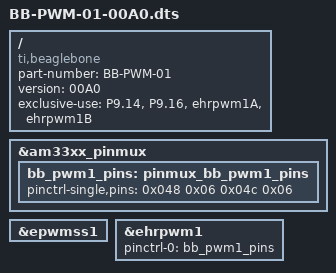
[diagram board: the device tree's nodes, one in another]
/dts-v1/;
/plugin/;

/*
 * BeagleBone Black PWM Overlay
 * Enables EHRPWM1A and EHRPWM1B on P9.14 and P9.16
 */

/ {
    compatible = "ti,beaglebone", "ti,beaglebone-black";
    
    /* identification */
    part-number = "BB-PWM-01";
    version = "00A0";
    
    /* state the resources this cape uses */
    exclusive-use =
        /* the pin header uses */
        "P9.14",    /* ehrpwm1A */
        "P9.16",    /* ehrpwm1B */
        /* the hardware IP uses */
        "ehrpwm1A",
        "ehrpwm1B";

    fragment@0 {
        target = <&am33xx_pinmux>;
        __overlay__ {
            bb_pwm1_pins: pinmux_bb_pwm1_pins {
                pinctrl-single,pins = <
                    0x048 0x06  /* P9_14: gpmc_a2.ehrpwm1A,  MODE6 */
                    0x04c 0x06  /* P9_16: gpmc_a3.ehrpwm1B,  MODE6 */
                >;
            };
        };
    };

    fragment@1 {
        target = <&epwmss1>;
        __overlay__ {
            status = "okay";
        };
    };

    fragment@2 {
        target = <&ehrpwm1>;
        __overlay__ {
            status = "okay";
            pinctrl-names = "default";
            pinctrl-0 = <&bb_pwm1_pins>;
        };
    };
};
